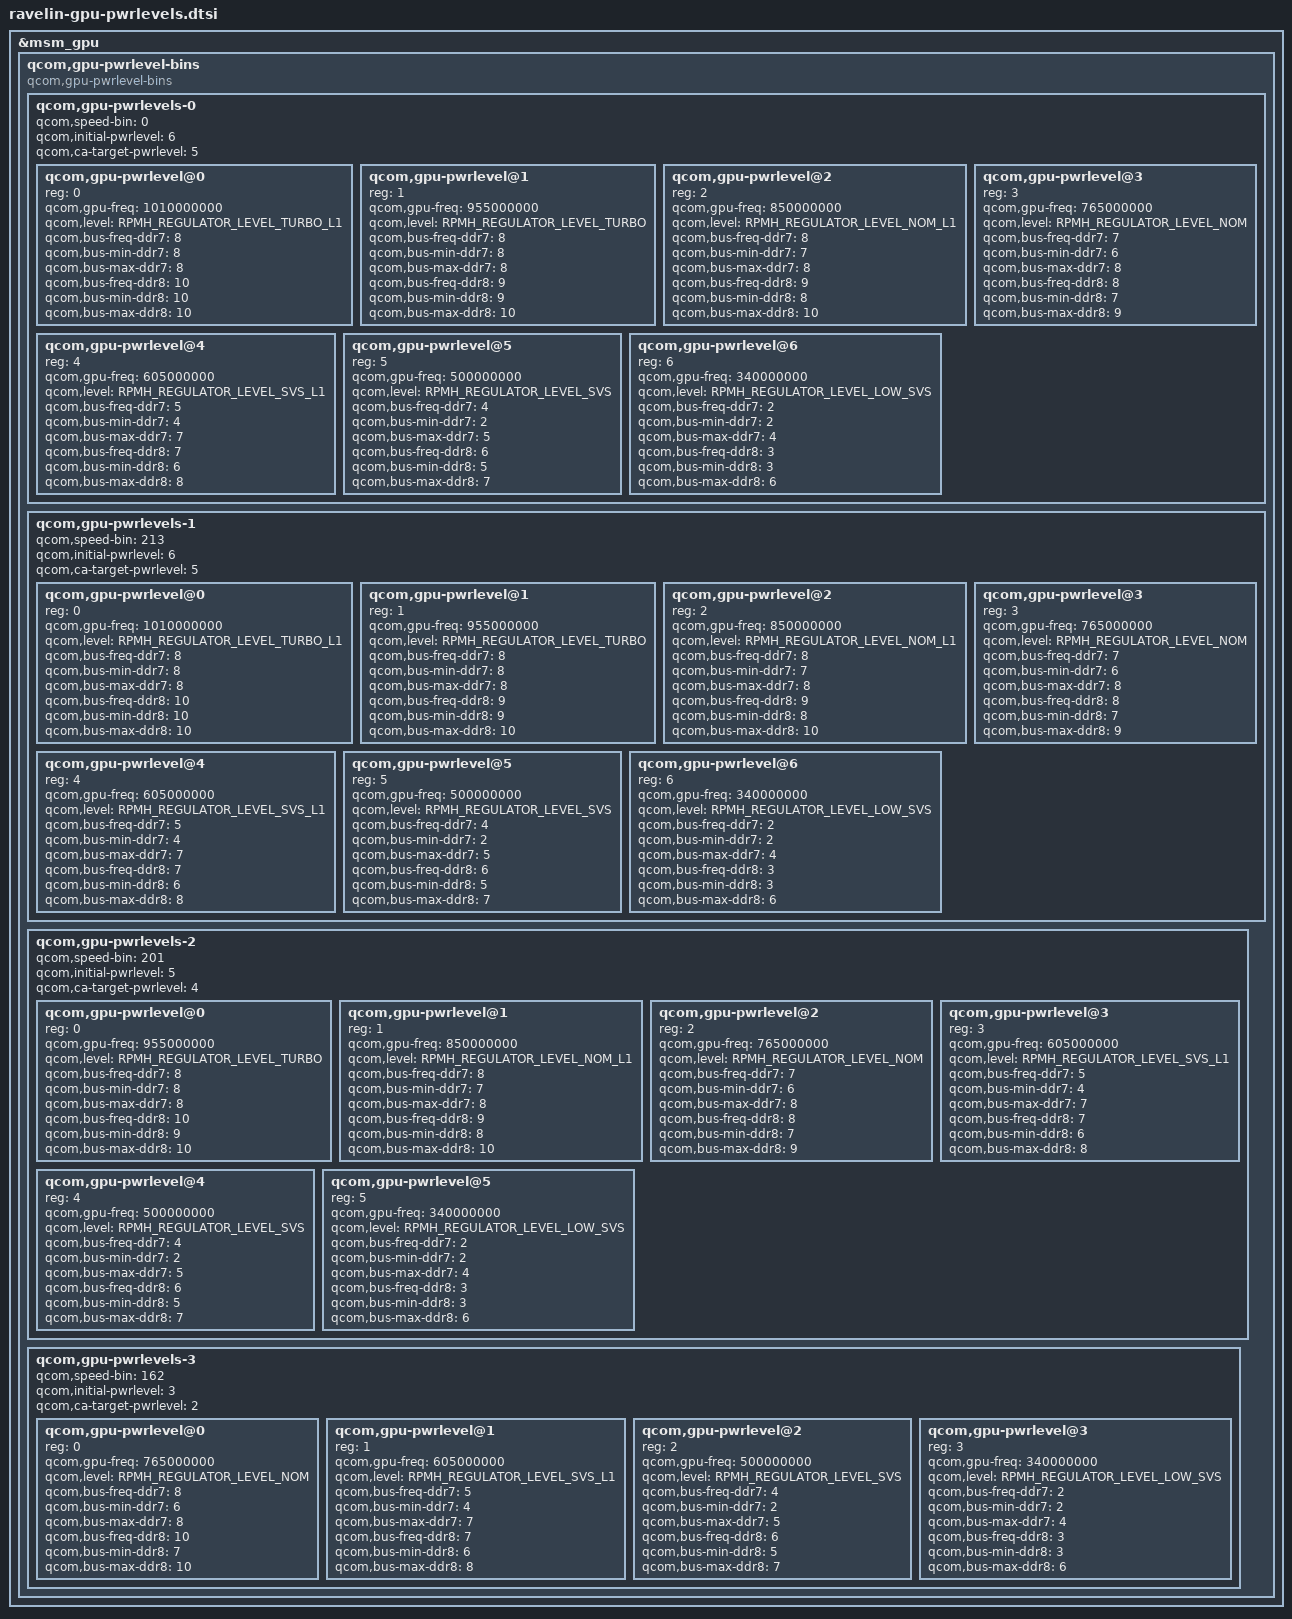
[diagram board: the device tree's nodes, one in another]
&msm_gpu {
	qcom,gpu-pwrlevel-bins {
		#address-cells = <1>;
		#size-cells = <0>;

		compatible = "qcom,gpu-pwrlevel-bins";

		qcom,gpu-pwrlevels-0 {
			#address-cells = <1>;
			#size-cells = <0>;

			qcom,speed-bin = <0>;
			qcom,initial-pwrlevel = <6>;
			qcom,ca-target-pwrlevel = <5>;

			qcom,gpu-pwrlevel@0 {
				reg = <0>;
				qcom,gpu-freq = <1010000000>;
				qcom,level = <RPMH_REGULATOR_LEVEL_TURBO_L1>;

				qcom,bus-freq-ddr7 = <8>;
				qcom,bus-min-ddr7 = <8>;
				qcom,bus-max-ddr7 = <8>;

				qcom,bus-freq-ddr8 = <10>;
				qcom,bus-min-ddr8 = <10>;
				qcom,bus-max-ddr8 = <10>;
			};

			qcom,gpu-pwrlevel@1 {
				reg = <1>;
				qcom,gpu-freq = <955000000>;
				qcom,level = <RPMH_REGULATOR_LEVEL_TURBO>;

				qcom,bus-freq-ddr7 = <8>;
				qcom,bus-min-ddr7 = <8>;
				qcom,bus-max-ddr7 = <8>;

				qcom,bus-freq-ddr8 = <9>;
				qcom,bus-min-ddr8 = <9>;
				qcom,bus-max-ddr8 = <10>;
			};

			qcom,gpu-pwrlevel@2 {
				reg = <2>;
				qcom,gpu-freq = <850000000>;
				qcom,level = <RPMH_REGULATOR_LEVEL_NOM_L1>;

				qcom,bus-freq-ddr7 = <8>;
				qcom,bus-min-ddr7 = <7>;
				qcom,bus-max-ddr7 = <8>;

				qcom,bus-freq-ddr8 = <9>;
				qcom,bus-min-ddr8 = <8>;
				qcom,bus-max-ddr8 = <10>;
			};

			qcom,gpu-pwrlevel@3 {
				reg = <3>;
				qcom,gpu-freq = <765000000>;
				qcom,level = <RPMH_REGULATOR_LEVEL_NOM>;

				qcom,bus-freq-ddr7 = <7>;
				qcom,bus-min-ddr7 = <6>;
				qcom,bus-max-ddr7 = <8>;

				qcom,bus-freq-ddr8 = <8>;
				qcom,bus-min-ddr8 = <7>;
				qcom,bus-max-ddr8 = <9>;
			};

			qcom,gpu-pwrlevel@4 {
				reg = <4>;
				qcom,gpu-freq = <605000000>;
				qcom,level = <RPMH_REGULATOR_LEVEL_SVS_L1>;

				qcom,bus-freq-ddr7 = <5>;
				qcom,bus-min-ddr7 = <4>;
				qcom,bus-max-ddr7 = <7>;

				qcom,bus-freq-ddr8 = <7>;
				qcom,bus-min-ddr8 = <6>;
				qcom,bus-max-ddr8 = <8>;
			};

			qcom,gpu-pwrlevel@5 {
				reg = <5>;
				qcom,gpu-freq = <500000000>;
				qcom,level = <RPMH_REGULATOR_LEVEL_SVS>;

				qcom,bus-freq-ddr7 = <4>;
				qcom,bus-min-ddr7 = <2>;
				qcom,bus-max-ddr7 = <5>;

				qcom,bus-freq-ddr8 = <6>;
				qcom,bus-min-ddr8 = <5>;
				qcom,bus-max-ddr8 = <7>;
			};

			qcom,gpu-pwrlevel@6 {
				reg = <6>;
				qcom,gpu-freq = <340000000>;
				qcom,level = <RPMH_REGULATOR_LEVEL_LOW_SVS>;

				qcom,bus-freq-ddr7 = <2>;
				qcom,bus-min-ddr7 = <2>;
				qcom,bus-max-ddr7 = <4>;

				qcom,bus-freq-ddr8 = <3>;
				qcom,bus-min-ddr8 = <3>;
				qcom,bus-max-ddr8 = <6>;
			};
		};

		qcom,gpu-pwrlevels-1 {
			#address-cells = <1>;
			#size-cells = <0>;

			qcom,speed-bin = <213>;
			qcom,initial-pwrlevel = <6>;
			qcom,ca-target-pwrlevel = <5>;

			qcom,gpu-pwrlevel@0 {
				reg = <0>;
				qcom,gpu-freq = <1010000000>;
				qcom,level = <RPMH_REGULATOR_LEVEL_TURBO_L1>;

				qcom,bus-freq-ddr7 = <8>;
				qcom,bus-min-ddr7 = <8>;
				qcom,bus-max-ddr7 = <8>;

				qcom,bus-freq-ddr8 = <10>;
				qcom,bus-min-ddr8 = <10>;
				qcom,bus-max-ddr8 = <10>;
			};

			qcom,gpu-pwrlevel@1 {
				reg = <1>;
				qcom,gpu-freq = <955000000>;
				qcom,level = <RPMH_REGULATOR_LEVEL_TURBO>;

				qcom,bus-freq-ddr7 = <8>;
				qcom,bus-min-ddr7 = <8>;
				qcom,bus-max-ddr7 = <8>;

				qcom,bus-freq-ddr8 = <9>;
				qcom,bus-min-ddr8 = <9>;
				qcom,bus-max-ddr8 = <10>;
			};

			qcom,gpu-pwrlevel@2 {
				reg = <2>;
				qcom,gpu-freq = <850000000>;
				qcom,level = <RPMH_REGULATOR_LEVEL_NOM_L1>;

				qcom,bus-freq-ddr7 = <8>;
				qcom,bus-min-ddr7 = <7>;
				qcom,bus-max-ddr7 = <8>;

				qcom,bus-freq-ddr8 = <9>;
				qcom,bus-min-ddr8 = <8>;
				qcom,bus-max-ddr8 = <10>;
			};

			qcom,gpu-pwrlevel@3 {
				reg = <3>;
				qcom,gpu-freq = <765000000>;
				qcom,level = <RPMH_REGULATOR_LEVEL_NOM>;

				qcom,bus-freq-ddr7 = <7>;
				qcom,bus-min-ddr7 = <6>;
				qcom,bus-max-ddr7 = <8>;

				qcom,bus-freq-ddr8 = <8>;
				qcom,bus-min-ddr8 = <7>;
				qcom,bus-max-ddr8 = <9>;
			};

			qcom,gpu-pwrlevel@4 {
				reg = <4>;
				qcom,gpu-freq = <605000000>;
				qcom,level = <RPMH_REGULATOR_LEVEL_SVS_L1>;

				qcom,bus-freq-ddr7 = <5>;
				qcom,bus-min-ddr7 = <4>;
				qcom,bus-max-ddr7 = <7>;

				qcom,bus-freq-ddr8 = <7>;
				qcom,bus-min-ddr8 = <6>;
				qcom,bus-max-ddr8 = <8>;
			};

			qcom,gpu-pwrlevel@5 {
				reg = <5>;
				qcom,gpu-freq = <500000000>;
				qcom,level = <RPMH_REGULATOR_LEVEL_SVS>;

				qcom,bus-freq-ddr7 = <4>;
				qcom,bus-min-ddr7 = <2>;
				qcom,bus-max-ddr7 = <5>;

				qcom,bus-freq-ddr8 = <6>;
				qcom,bus-min-ddr8 = <5>;
				qcom,bus-max-ddr8 = <7>;
			};

			qcom,gpu-pwrlevel@6 {
				reg = <6>;
				qcom,gpu-freq = <340000000>;
				qcom,level = <RPMH_REGULATOR_LEVEL_LOW_SVS>;

				qcom,bus-freq-ddr7 = <2>;
				qcom,bus-min-ddr7 = <2>;
				qcom,bus-max-ddr7 = <4>;

				qcom,bus-freq-ddr8 = <3>;
				qcom,bus-min-ddr8 = <3>;
				qcom,bus-max-ddr8 = <6>;
			};
		};

		qcom,gpu-pwrlevels-2 {
			#address-cells = <1>;
			#size-cells = <0>;

			qcom,speed-bin = <201>;
			qcom,initial-pwrlevel = <5>;
			qcom,ca-target-pwrlevel = <4>;

			qcom,gpu-pwrlevel@0 {
				reg = <0>;
				qcom,gpu-freq = <955000000>;
				qcom,level = <RPMH_REGULATOR_LEVEL_TURBO>;

				qcom,bus-freq-ddr7 = <8>;
				qcom,bus-min-ddr7 = <8>;
				qcom,bus-max-ddr7 = <8>;

				qcom,bus-freq-ddr8 = <10>;
				qcom,bus-min-ddr8 = <9>;
				qcom,bus-max-ddr8 = <10>;
			};

			qcom,gpu-pwrlevel@1 {
				reg = <1>;
				qcom,gpu-freq = <850000000>;
				qcom,level = <RPMH_REGULATOR_LEVEL_NOM_L1>;

				qcom,bus-freq-ddr7 = <8>;
				qcom,bus-min-ddr7 = <7>;
				qcom,bus-max-ddr7 = <8>;

				qcom,bus-freq-ddr8 = <9>;
				qcom,bus-min-ddr8 = <8>;
				qcom,bus-max-ddr8 = <10>;
			};

			qcom,gpu-pwrlevel@2 {
				reg = <2>;
				qcom,gpu-freq = <765000000>;
				qcom,level = <RPMH_REGULATOR_LEVEL_NOM>;

				qcom,bus-freq-ddr7 = <7>;
				qcom,bus-min-ddr7 = <6>;
				qcom,bus-max-ddr7 = <8>;

				qcom,bus-freq-ddr8 = <8>;
				qcom,bus-min-ddr8 = <7>;
				qcom,bus-max-ddr8 = <9>;
			};

			qcom,gpu-pwrlevel@3 {
				reg = <3>;
				qcom,gpu-freq = <605000000>;
				qcom,level = <RPMH_REGULATOR_LEVEL_SVS_L1>;

				qcom,bus-freq-ddr7 = <5>;
				qcom,bus-min-ddr7 = <4>;
				qcom,bus-max-ddr7 = <7>;

				qcom,bus-freq-ddr8 = <7>;
				qcom,bus-min-ddr8 = <6>;
				qcom,bus-max-ddr8 = <8>;
			};

			qcom,gpu-pwrlevel@4 {
				reg = <4>;
				qcom,gpu-freq = <500000000>;
				qcom,level = <RPMH_REGULATOR_LEVEL_SVS>;

				qcom,bus-freq-ddr7 = <4>;
				qcom,bus-min-ddr7 = <2>;
				qcom,bus-max-ddr7 = <5>;

				qcom,bus-freq-ddr8 = <6>;
				qcom,bus-min-ddr8 = <5>;
				qcom,bus-max-ddr8 = <7>;
			};

			qcom,gpu-pwrlevel@5 {
				reg = <5>;
				qcom,gpu-freq = <340000000>;
				qcom,level = <RPMH_REGULATOR_LEVEL_LOW_SVS>;

				qcom,bus-freq-ddr7 = <2>;
				qcom,bus-min-ddr7 = <2>;
				qcom,bus-max-ddr7 = <4>;

				qcom,bus-freq-ddr8 = <3>;
				qcom,bus-min-ddr8 = <3>;
				qcom,bus-max-ddr8 = <6>;
			};
		};

		qcom,gpu-pwrlevels-3 {
			#address-cells = <1>;
			#size-cells = <0>;

			qcom,speed-bin = <162>;
			qcom,initial-pwrlevel = <3>;
			qcom,ca-target-pwrlevel = <2>;

			qcom,gpu-pwrlevel@0 {
				reg = <0>;
				qcom,gpu-freq = <765000000>;
				qcom,level = <RPMH_REGULATOR_LEVEL_NOM>;

				qcom,bus-freq-ddr7 = <8>;
				qcom,bus-min-ddr7 = <6>;
				qcom,bus-max-ddr7 = <8>;

				qcom,bus-freq-ddr8 = <10>;
				qcom,bus-min-ddr8 = <7>;
				qcom,bus-max-ddr8 = <10>;
			};

			qcom,gpu-pwrlevel@1 {
				reg = <1>;
				qcom,gpu-freq = <605000000>;
				qcom,level = <RPMH_REGULATOR_LEVEL_SVS_L1>;

				qcom,bus-freq-ddr7 = <5>;
				qcom,bus-min-ddr7 = <4>;
				qcom,bus-max-ddr7 = <7>;

				qcom,bus-freq-ddr8 = <7>;
				qcom,bus-min-ddr8 = <6>;
				qcom,bus-max-ddr8 = <8>;
			};

			qcom,gpu-pwrlevel@2 {
				reg = <2>;
				qcom,gpu-freq = <500000000>;
				qcom,level = <RPMH_REGULATOR_LEVEL_SVS>;

				qcom,bus-freq-ddr7 = <4>;
				qcom,bus-min-ddr7 = <2>;
				qcom,bus-max-ddr7 = <5>;

				qcom,bus-freq-ddr8 = <6>;
				qcom,bus-min-ddr8 = <5>;
				qcom,bus-max-ddr8 = <7>;
			};

			qcom,gpu-pwrlevel@3 {
				reg = <3>;
				qcom,gpu-freq = <340000000>;
				qcom,level = <RPMH_REGULATOR_LEVEL_LOW_SVS>;

				qcom,bus-freq-ddr7 = <2>;
				qcom,bus-min-ddr7 = <2>;
				qcom,bus-max-ddr7 = <4>;

				qcom,bus-freq-ddr8 = <3>;
				qcom,bus-min-ddr8 = <3>;
				qcom,bus-max-ddr8 = <6>;
			};
		};
	};
};
